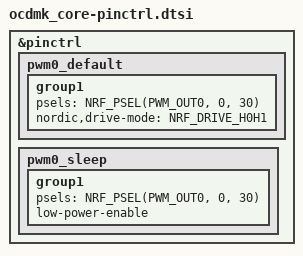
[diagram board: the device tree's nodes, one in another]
/*
 * Copyright (c) 2024 OCDMK Contributors
 *
 * SPDX-License-Identifier: MIT
 *
 * OCDMK Core Pin Control Configuration
 */

&pinctrl {
    /* PWM0: LED on P0.30 (controls MCP1662 LED boost driver) */
    pwm0_default: pwm0_default {
        group1 {
            psels = <NRF_PSEL(PWM_OUT0, 0, 30)>;
            /* Maximum drive strength (H0H1) for better signal quality */
            nordic,drive-mode = <NRF_DRIVE_H0H1>;
        };
    };

    pwm0_sleep: pwm0_sleep {
        group1 {
            psels = <NRF_PSEL(PWM_OUT0, 0, 30)>;
            low-power-enable;
        };
    };
};

